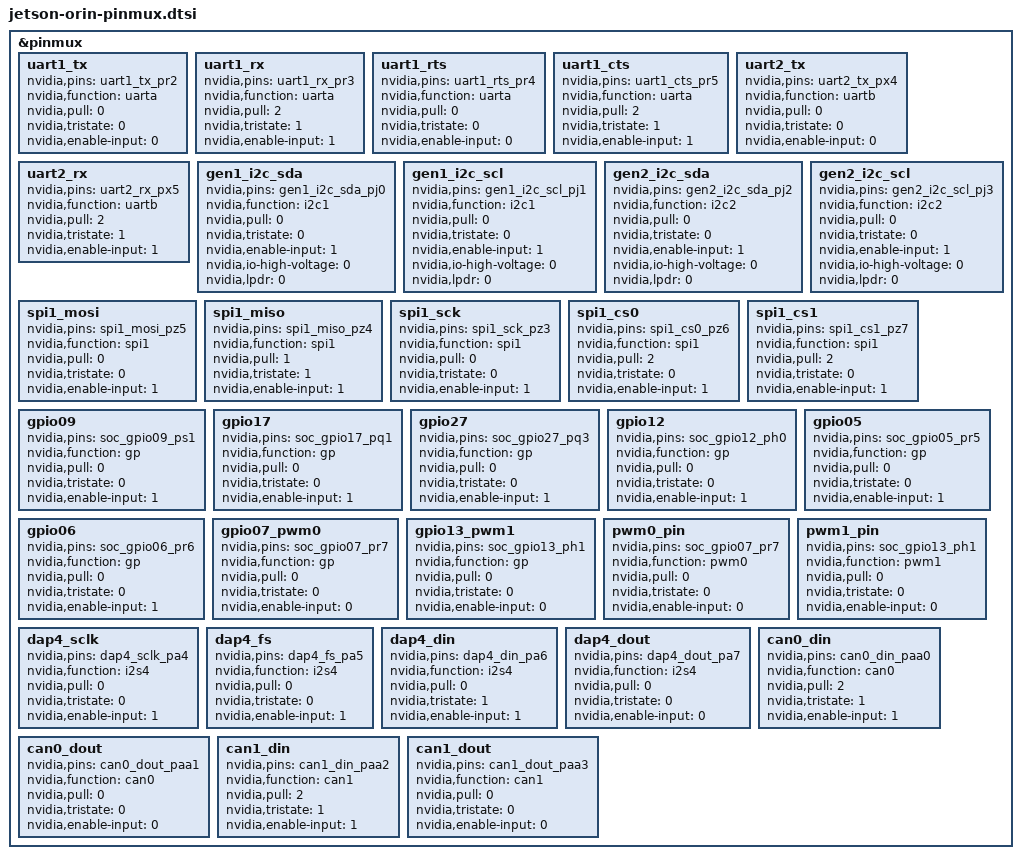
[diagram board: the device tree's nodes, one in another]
// SPDX-License-Identifier: GPL-2.0
/*
 * Jetson Orin Common Pinmux Configurations
 *
 * This file contains reusable pinmux configurations for common peripherals
 * on the Jetson Orin 40-pin expansion header.
 *
 * Usage: Include this file in your device tree or overlay:
 *   #include "jetson-orin-pinmux.dtsi"
 */

/*
 * UART Pinmux Configurations
 * ===========================
 */

/* UART1 (Primary UART on 40-pin header) */
&pinmux {
    uart1_tx {
        nvidia,pins = "uart1_tx_pr2";
        nvidia,function = "uarta";
        nvidia,pull = <0>;  /* TEGRA_PIN_PULL_NONE */
        nvidia,tristate = <0>;
        nvidia,enable-input = <0>;
    };

    uart1_rx {
        nvidia,pins = "uart1_rx_pr3";
        nvidia,function = "uarta";
        nvidia,pull = <2>;  /* TEGRA_PIN_PULL_UP */
        nvidia,tristate = <1>;
        nvidia,enable-input = <1>;
    };

    uart1_rts {
        nvidia,pins = "uart1_rts_pr4";
        nvidia,function = "uarta";
        nvidia,pull = <0>;
        nvidia,tristate = <0>;
        nvidia,enable-input = <0>;
    };

    uart1_cts {
        nvidia,pins = "uart1_cts_pr5";
        nvidia,function = "uarta";
        nvidia,pull = <2>;
        nvidia,tristate = <1>;
        nvidia,enable-input = <1>;
    };
};

/* UART2 (Secondary UART) */
&pinmux {
    uart2_tx {
        nvidia,pins = "uart2_tx_px4";
        nvidia,function = "uartb";
        nvidia,pull = <0>;
        nvidia,tristate = <0>;
        nvidia,enable-input = <0>;
    };

    uart2_rx {
        nvidia,pins = "uart2_rx_px5";
        nvidia,function = "uartb";
        nvidia,pull = <2>;
        nvidia,tristate = <1>;
        nvidia,enable-input = <1>;
    };
};

/*
 * I2C Pinmux Configurations
 * ==========================
 */

/* I2C1 (General purpose I2C on 40-pin header) */
&pinmux {
    gen1_i2c_sda {
        nvidia,pins = "gen1_i2c_sda_pj0";
        nvidia,function = "i2c1";
        nvidia,pull = <0>;  /* External pull-ups required */
        nvidia,tristate = <0>;
        nvidia,enable-input = <1>;
        nvidia,io-high-voltage = <0>;  /* 3.3V */
        nvidia,lpdr = <0>;
    };

    gen1_i2c_scl {
        nvidia,pins = "gen1_i2c_scl_pj1";
        nvidia,function = "i2c1";
        nvidia,pull = <0>;
        nvidia,tristate = <0>;
        nvidia,enable-input = <1>;
        nvidia,io-high-voltage = <0>;
        nvidia,lpdr = <0>;
    };
};

/* I2C2 */
&pinmux {
    gen2_i2c_sda {
        nvidia,pins = "gen2_i2c_sda_pj2";
        nvidia,function = "i2c2";
        nvidia,pull = <0>;
        nvidia,tristate = <0>;
        nvidia,enable-input = <1>;
        nvidia,io-high-voltage = <0>;
        nvidia,lpdr = <0>;
    };

    gen2_i2c_scl {
        nvidia,pins = "gen2_i2c_scl_pj3";
        nvidia,function = "i2c2";
        nvidia,pull = <0>;
        nvidia,tristate = <0>;
        nvidia,enable-input = <1>;
        nvidia,io-high-voltage = <0>;
        nvidia,lpdr = <0>;
    };
};

/*
 * SPI Pinmux Configurations
 * ==========================
 */

/* SPI1 (Primary SPI on 40-pin header) */
&pinmux {
    spi1_mosi {
        nvidia,pins = "spi1_mosi_pz5";
        nvidia,function = "spi1";
        nvidia,pull = <0>;
        nvidia,tristate = <0>;
        nvidia,enable-input = <1>;
    };

    spi1_miso {
        nvidia,pins = "spi1_miso_pz4";
        nvidia,function = "spi1";
        nvidia,pull = <1>;  /* Pull-down */
        nvidia,tristate = <1>;
        nvidia,enable-input = <1>;
    };

    spi1_sck {
        nvidia,pins = "spi1_sck_pz3";
        nvidia,function = "spi1";
        nvidia,pull = <0>;
        nvidia,tristate = <0>;
        nvidia,enable-input = <1>;
    };

    spi1_cs0 {
        nvidia,pins = "spi1_cs0_pz6";
        nvidia,function = "spi1";
        nvidia,pull = <2>;  /* Pull-up */
        nvidia,tristate = <0>;
        nvidia,enable-input = <1>;
    };

    spi1_cs1 {
        nvidia,pins = "spi1_cs1_pz7";
        nvidia,function = "spi1";
        nvidia,pull = <2>;
        nvidia,tristate = <0>;
        nvidia,enable-input = <1>;
    };
};

/*
 * GPIO Pinmux Configurations
 * ===========================
 * Configure pins as general-purpose I/O
 */

/* Common GPIO pins on 40-pin header */
&pinmux {
    /* Pin 7 - GPIO09 */
    gpio09 {
        nvidia,pins = "soc_gpio09_ps1";
        nvidia,function = "gp";
        nvidia,pull = <0>;
        nvidia,tristate = <0>;
        nvidia,enable-input = <1>;  /* Bidirectional */
    };

    /* Pin 11 - GPIO17 */
    gpio17 {
        nvidia,pins = "soc_gpio17_pq1";
        nvidia,function = "gp";
        nvidia,pull = <0>;
        nvidia,tristate = <0>;
        nvidia,enable-input = <1>;
    };

    /* Pin 13 - GPIO27 */
    gpio27 {
        nvidia,pins = "soc_gpio27_pq3";
        nvidia,function = "gp";
        nvidia,pull = <0>;
        nvidia,tristate = <0>;
        nvidia,enable-input = <1>;
    };

    /* Pin 15 - GPIO12 */
    gpio12 {
        nvidia,pins = "soc_gpio12_ph0";
        nvidia,function = "gp";
        nvidia,pull = <0>;
        nvidia,tristate = <0>;
        nvidia,enable-input = <1>;
    };

    /* Pin 29 - GPIO05 */
    gpio05 {
        nvidia,pins = "soc_gpio05_pr5";
        nvidia,function = "gp";
        nvidia,pull = <0>;
        nvidia,tristate = <0>;
        nvidia,enable-input = <1>;
    };

    /* Pin 31 - GPIO06 */
    gpio06 {
        nvidia,pins = "soc_gpio06_pr6";
        nvidia,function = "gp";
        nvidia,pull = <0>;
        nvidia,tristate = <0>;
        nvidia,enable-input = <1>;
    };

    /* Pin 32 - GPIO07 / PWM0 */
    gpio07_pwm0 {
        nvidia,pins = "soc_gpio07_pr7";
        nvidia,function = "gp";  /* Use "pwm0" for PWM function */
        nvidia,pull = <0>;
        nvidia,tristate = <0>;
        nvidia,enable-input = <0>;
    };

    /* Pin 33 - GPIO13 / PWM1 */
    gpio13_pwm1 {
        nvidia,pins = "soc_gpio13_ph1";
        nvidia,function = "gp";  /* Use "pwm1" for PWM function */
        nvidia,pull = <0>;
        nvidia,tristate = <0>;
        nvidia,enable-input = <0>;
    };
};

/*
 * PWM Pinmux Configurations
 * ==========================
 */

/* PWM0 on Pin 32 */
&pinmux {
    pwm0_pin {
        nvidia,pins = "soc_gpio07_pr7";
        nvidia,function = "pwm0";
        nvidia,pull = <0>;
        nvidia,tristate = <0>;
        nvidia,enable-input = <0>;
    };
};

/* PWM1 on Pin 33 */
&pinmux {
    pwm1_pin {
        nvidia,pins = "soc_gpio13_ph1";
        nvidia,function = "pwm1";
        nvidia,pull = <0>;
        nvidia,tristate = <0>;
        nvidia,enable-input = <0>;
    };
};

/*
 * I2S Audio Pinmux Configurations
 * ================================
 */

&pinmux {
    dap4_sclk {
        nvidia,pins = "dap4_sclk_pa4";
        nvidia,function = "i2s4";
        nvidia,pull = <0>;
        nvidia,tristate = <0>;
        nvidia,enable-input = <1>;
    };

    dap4_fs {
        nvidia,pins = "dap4_fs_pa5";
        nvidia,function = "i2s4";
        nvidia,pull = <0>;
        nvidia,tristate = <0>;
        nvidia,enable-input = <1>;
    };

    dap4_din {
        nvidia,pins = "dap4_din_pa6";
        nvidia,function = "i2s4";
        nvidia,pull = <0>;
        nvidia,tristate = <1>;
        nvidia,enable-input = <1>;
    };

    dap4_dout {
        nvidia,pins = "dap4_dout_pa7";
        nvidia,function = "i2s4";
        nvidia,pull = <0>;
        nvidia,tristate = <0>;
        nvidia,enable-input = <0>;
    };
};

/*
 * CAN Bus Pinmux Configurations
 * ==============================
 */

&pinmux {
    can0_din {
        nvidia,pins = "can0_din_paa0";
        nvidia,function = "can0";
        nvidia,pull = <2>;  /* Pull-up */
        nvidia,tristate = <1>;
        nvidia,enable-input = <1>;
    };

    can0_dout {
        nvidia,pins = "can0_dout_paa1";
        nvidia,function = "can0";
        nvidia,pull = <0>;
        nvidia,tristate = <0>;
        nvidia,enable-input = <0>;
    };

    can1_din {
        nvidia,pins = "can1_din_paa2";
        nvidia,function = "can1";
        nvidia,pull = <2>;
        nvidia,tristate = <1>;
        nvidia,enable-input = <1>;
    };

    can1_dout {
        nvidia,pins = "can1_dout_paa3";
        nvidia,function = "can1";
        nvidia,pull = <0>;
        nvidia,tristate = <0>;
        nvidia,enable-input = <0>;
    };
};

/*
 * Pin Function Reference
 * =======================
 *
 * Common nvidia,function values:
 * - "gp": General purpose GPIO
 * - "uarta", "uartb", "uartc", etc.: UART functions
 * - "i2c1", "i2c2", etc.: I2C functions
 * - "spi1", "spi2", etc.: SPI functions
 * - "pwm0", "pwm1", etc.: PWM functions
 * - "i2s1", "i2s2", etc.: I2S audio functions
 * - "can0", "can1": CAN bus functions
 *
 * Pull configurations (nvidia,pull):
 * - 0: TEGRA_PIN_PULL_NONE
 * - 1: TEGRA_PIN_PULL_DOWN
 * - 2: TEGRA_PIN_PULL_UP
 *
 * Tristate (nvidia,tristate):
 * - 0: TEGRA_PIN_DISABLE (normal operation)
 * - 1: TEGRA_PIN_ENABLE (high-Z, for inputs)
 *
 * Input enable (nvidia,enable-input):
 * - 0: TEGRA_PIN_DISABLE (output only)
 * - 1: TEGRA_PIN_ENABLE (input or bidirectional)
 */
